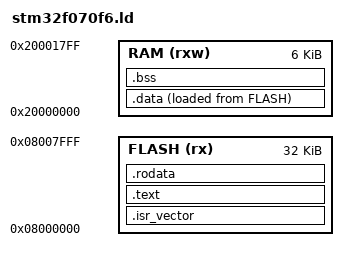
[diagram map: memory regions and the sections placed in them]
ENTRY(Reset_Handler)

MEMORY
{
    FLASH ( rx )    : ORIGIN = 0x08000000, LENGTH = 32K
    RAM ( rxw )     : ORIGIN = 0x20000000, LENGTH = 6K
}

/* Highest address of the user mode stack */
_estack = ORIGIN(RAM) + LENGTH(RAM); /* end of "RAM" Ram type memory */
_Min_Stack_Size = 0x800; /* required amount of stack */

/* Sections */
SECTIONS
{
  /* The startup code into "FLASH" Rom type memory */
  .isr_vector :
  {
    . = ALIGN(4);
    KEEP(*(.isr_vector)) /* Startup code */
    . = ALIGN(4);
  } >FLASH

  /* The program code and other data into "FLASH" Rom type memory */
  .text :
  {
    . = ALIGN(4);
    *(.text)
    *(.text*)
    *(.glue_7)
    *(.glue_7t)
    *(.eh_frame)

    KEEP (*(.init))
    KEEP (*(.fini))

    . = ALIGN(4);
    _etext = .;
  } >FLASH

  .rodata :
  {
    . = ALIGN(4);
    *(.rodata)
    *(.rodata*)
    . = ALIGN(4);
  } >FLASH

  /* Used by the startup to initialize data */
  _sidata = LOADADDR(.data);
  .data :
  {
    . = ALIGN(4);
    _sdata = .;        /* create a global symbol at data start */
    *(.data)           /* .data sections */
    *(.data*)          /* .data* sections */
    *(.RamFunc)        /* .RamFunc sections */
    *(.RamFunc*)       /* .RamFunc* sections */

    . = ALIGN(4);
    _edata = .;        /* define a global symbol at data end */

  } >RAM AT> FLASH

  . = ALIGN(4);
  .bss :
  {
    /* This is used by the startup in order to initialize the .bss section */
    _sbss = .;
    *(.bss)
    *(.bss*)
    *(COMMON)

    . = ALIGN(4);
    _ebss = .;
  } >RAM

  /DISCARD/ :
  {
    libc.a ( * )
    libm.a ( * )
    libgcc.a ( * )
  }
}
